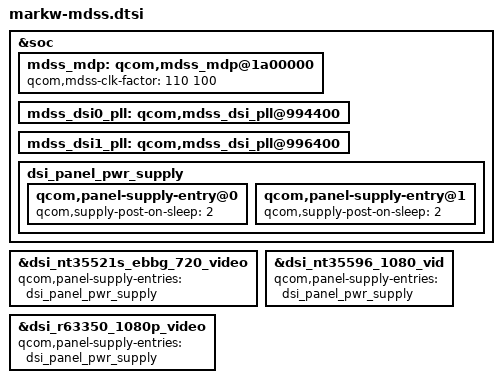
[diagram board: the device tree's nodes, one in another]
/*
 * Copyright (c) 2015-2017, The Linux Foundation. All rights reserved.
 * Copyright (C) 2019 XiaoMi, Inc.
 *
 * This program is free software; you can redistribute it and/or modify
 * it under the terms of the GNU General Public License version 2 and
 * only version 2 as published by the Free Software Foundation.
 *
 * This program is distributed in the hope that it will be useful,
 * but WITHOUT ANY WARRANTY; without even the implied warranty of
 * MERCHANTABILITY or FITNESS FOR A PARTICULAR PURPOSE.  See the
 * GNU General Public License for more details.
 */

/* msm8953-mdss */
&soc {
	mdss_mdp: qcom,mdss_mdp@1a00000 {
			qcom,mdss-clk-factor = <110 100>;	/* 1.10 times */
	};
};

/* msm8953-mdss-pll */
&soc {
	mdss_dsi0_pll: qcom,mdss_dsi_pll@994400 {
		/delete-property/ qcom,dsi-pll-ssc-en;
		/delete-property/ qcom,dsi-pll-ssc-mode;
	};
	mdss_dsi1_pll: qcom,mdss_dsi_pll@996400 {
		/delete-property/ qcom,dsi-pll-ssc-en;
		/delete-property/ qcom,dsi-pll-ssc-mode;
	};
};

/* msm8953-mdss-panels */
#include "panels/dsi-panel-nt35521s-ebbg-720p-video.dtsi"
#include "panels/dsi-panel-nt35596-ebbg-1080p-video.dtsi"
#include "panels/dsi-panel-r63350-tianma-1080p-video.dtsi"

&soc {
	dsi_panel_pwr_supply: dsi_panel_pwr_supply {
		qcom,panel-supply-entry@0 {
			qcom,supply-post-on-sleep= <2>;
		};
		qcom,panel-supply-entry@1 {
			qcom,supply-post-on-sleep= <2>;
		};
	};
};

&dsi_nt35521s_ebbg_720_video {
	qcom,panel-supply-entries = <&dsi_panel_pwr_supply>;
};

&dsi_nt35596_1080_vid {
	qcom,panel-supply-entries = <&dsi_panel_pwr_supply>;
};

&dsi_r63350_1080p_video {
	qcom,panel-supply-entries = <&dsi_panel_pwr_supply>;
};



